# STM32WB06 register map
File version: 1.0
Registers are 32-bit, read-write, reset 0x0 unless marked. A register's access mark holds for its fields unless they carry their own. Offsets are from the block's base; [hi:lo] are bit positions; {n}, {i} and the like mark numbered series; 'fields as' and 'values as' point back to an identical list.

## RRM
Base 0x60001400
0x00 RRM_ID
  [3:0] IDENTIFICATION
0x04 RRM_CTRL
  [1:0] PRIORITY
0x10 UDRA_CTRL0
  [0] RELOAD_RDCFGPTR
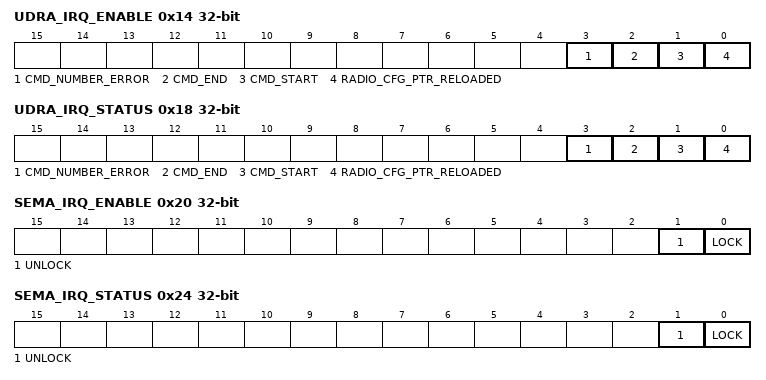
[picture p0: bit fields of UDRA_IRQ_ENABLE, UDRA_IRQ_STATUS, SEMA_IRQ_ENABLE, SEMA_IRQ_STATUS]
0x14 UDRA_IRQ_ENABLE
  [3] CMD_NUMBER_ERROR, [2] CMD_END, [1] CMD_START, [0] RADIO_CFG_PTR_RELOADED
0x18 UDRA_IRQ_STATUS
  fields as UDRA_IRQ_ENABLE
0x1C UDRA_RADIO_CFG_PTR
  [31:0] RADIO_CONFIG_ADDRESS
0x20 SEMA_IRQ_ENABLE
  [1] UNLOCK, [0] LOCK
0x24 SEMA_IRQ_STATUS
  [1] UNLOCK, [0] LOCK
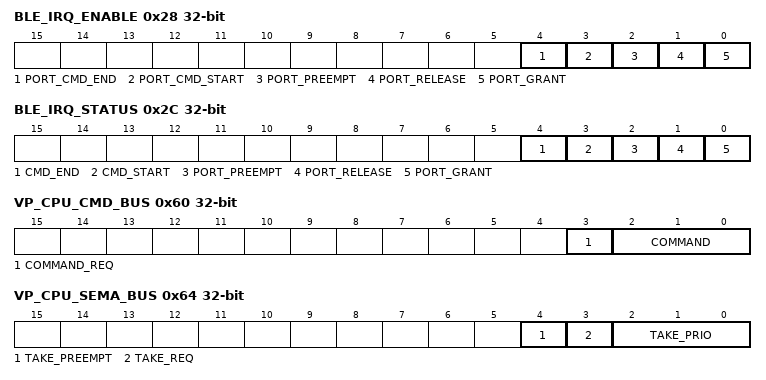
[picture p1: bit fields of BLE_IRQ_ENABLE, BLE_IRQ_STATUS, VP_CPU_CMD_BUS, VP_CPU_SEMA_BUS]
0x28 BLE_IRQ_ENABLE
  [4] PORT_CMD_END, [3] PORT_CMD_START, [2] PORT_PREEMPT, [1] PORT_RELEASE, [0] PORT_GRANT
0x2C BLE_IRQ_STATUS
  [4] CMD_END, [3] CMD_START, [2] PORT_PREEMPT, [1] PORT_RELEASE, [0] PORT_GRANT
0x60 VP_CPU_CMD_BUS
  [3] COMMAND_REQ, [2:0] COMMAND
0x64 VP_CPU_SEMA_BUS
  [4] TAKE_PREEMPT, [3] TAKE_REQ, [2:0] TAKE_PRIO
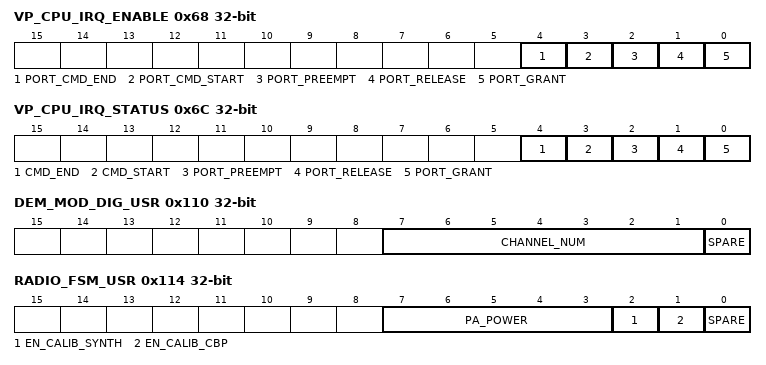
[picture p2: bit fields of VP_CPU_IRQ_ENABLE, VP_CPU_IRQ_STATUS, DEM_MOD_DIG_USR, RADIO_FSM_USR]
0x68 VP_CPU_IRQ_ENABLE
  fields as BLE_IRQ_ENABLE
0x6C VP_CPU_IRQ_STATUS
  fields as BLE_IRQ_STATUS
{0x100+4i} AA{i}_DIG_USR (i=0..3)
  [7:0] AA_{8i+7}_{8i}
0x110 DEM_MOD_DIG_USR
  [7:1] CHANNEL_NUM, [0] SPARE
0x114 RADIO_FSM_USR
  [7:3] PA_POWER, [2] EN_CALIB_SYNTH, [1] EN_CALIB_CBP, [0] SPARE
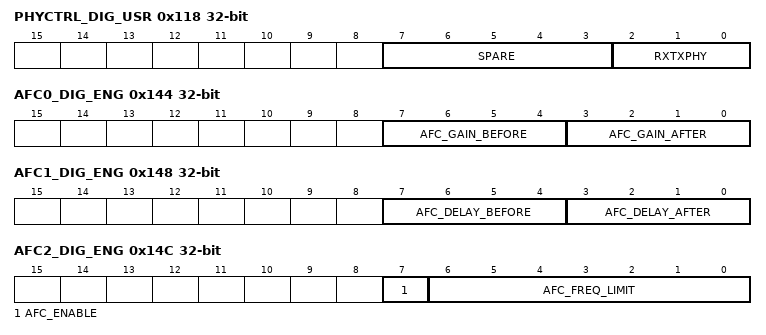
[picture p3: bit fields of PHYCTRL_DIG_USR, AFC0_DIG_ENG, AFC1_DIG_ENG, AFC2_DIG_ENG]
0x118 PHYCTRL_DIG_USR
  [7:3] SPARE, [2:0] RXTXPHY
0x144 AFC0_DIG_ENG
  [7:4] AFC_GAIN_BEFORE, [3:0] AFC_GAIN_AFTER
0x148 AFC1_DIG_ENG
  [7:4] AFC_DELAY_BEFORE, [3:0] AFC_DELAY_AFTER
0x14C AFC2_DIG_ENG
  [7] AFC_ENABLE, [6:0] AFC_FREQ_LIMIT
0x150 AFC3_DIG_ENG
  [7:0] AFC_MINMAX_LIMIT
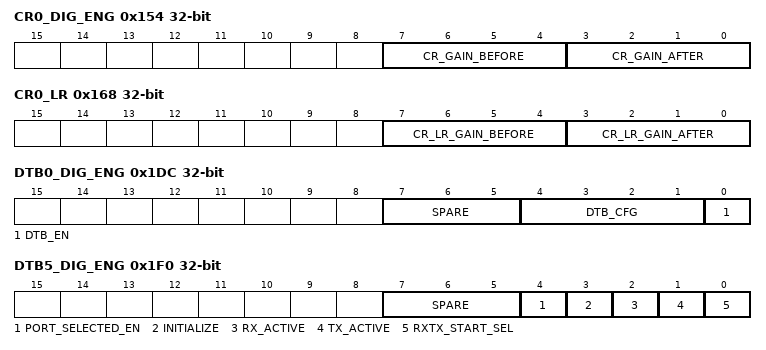
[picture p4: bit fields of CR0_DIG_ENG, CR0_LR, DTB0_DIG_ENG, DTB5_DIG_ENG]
0x154 CR0_DIG_ENG
  [7:4] CR_GAIN_BEFORE, [3:0] CR_GAIN_AFTER
0x168 CR0_LR
  [7:4] CR_LR_GAIN_BEFORE, [3:0] CR_LR_GAIN_AFTER
0x16C VIT_CONF_DIG_ENG
  [7:0] VIT_CONF
0x184 LR_PD_THR_DIG_ENG
  [7:0] LR_PD_THR
0x188 LR_RSSI_THR_DIG_ENG
  [7:0] LR_RSSI_THR
0x18C LR_AAC_THR_DIG_ENG
  [7:0] LR_AAC_THR
0x1DC DTB0_DIG_ENG
  [7:5] SPARE, [4:1] DTB_CFG, [0] DTB_EN
0x1F0 DTB5_DIG_ENG
  [7:5] SPARE, [4] PORT_SELECTED_EN, [3] INITIALIZE, [2] RX_ACTIVE, [1] TX_ACTIVE, [0] RXTX_START_SEL
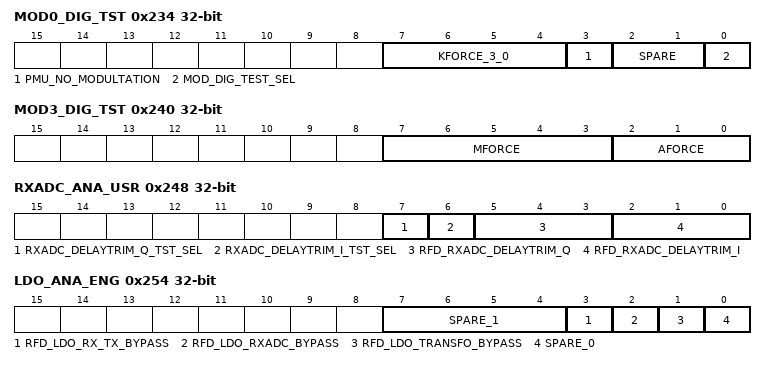
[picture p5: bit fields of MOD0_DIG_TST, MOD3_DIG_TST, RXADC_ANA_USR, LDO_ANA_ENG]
0x234 MOD0_DIG_TST
  [7:4] KFORCE_3_0, [3] PMU_NO_MODULTATION, [2:1] SPARE, [0] MOD_DIG_TEST_SEL
0x238 MOD1_DIG_TST
  [7:0] KFORCE_11_4
0x23C MOD2_DIG_TST
  [7:0] KFORCE_19_12
0x240 MOD3_DIG_TST
  [7:3] MFORCE, [2:0] AFORCE
0x248 RXADC_ANA_USR
  [7] RXADC_DELAYTRIM_Q_TST_SEL, [6] RXADC_DELAYTRIM_I_TST_SEL, [5:3] RFD_RXADC_DELAYTRIM_Q, [2:0] RFD_RXADC_DELAYTRIM_I
0x254 LDO_ANA_ENG
  [7:4] SPARE_1, [3] RFD_LDO_RX_TX_BYPASS, [2] RFD_LDO_RXADC_BYPASS, [1] RFD_LDO_TRANSFO_BYPASS, [0] SPARE_0
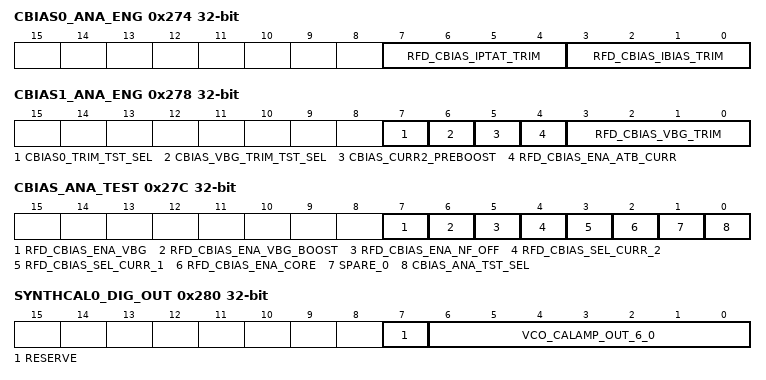
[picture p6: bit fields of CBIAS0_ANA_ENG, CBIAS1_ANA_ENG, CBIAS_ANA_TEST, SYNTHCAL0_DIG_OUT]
0x274 CBIAS0_ANA_ENG
  [7:4] RFD_CBIAS_IPTAT_TRIM, [3:0] RFD_CBIAS_IBIAS_TRIM
0x278 CBIAS1_ANA_ENG
  [7] CBIAS0_TRIM_TST_SEL, [6] CBIAS_VBG_TRIM_TST_SEL, [5] CBIAS_CURR2_PREBOOST, [4] RFD_CBIAS_ENA_ATB_CURR, [3:0] RFD_CBIAS_VBG_TRIM
0x27C CBIAS_ANA_TEST
  [7] RFD_CBIAS_ENA_VBG, [6] RFD_CBIAS_ENA_VBG_BOOST, [5] RFD_CBIAS_ENA_NF_OFF, [4] RFD_CBIAS_SEL_CURR_2, [3] RFD_CBIAS_SEL_CURR_1, [2] RFD_CBIAS_ENA_CORE, [1] SPARE_0, [0] CBIAS_ANA_TST_SEL
0x280 SYNTHCAL0_DIG_OUT
  [7] RESERVE, [6:0] VCO_CALAMP_OUT_6_0
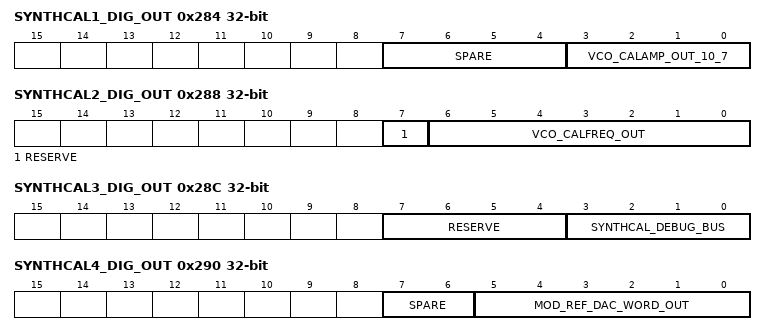
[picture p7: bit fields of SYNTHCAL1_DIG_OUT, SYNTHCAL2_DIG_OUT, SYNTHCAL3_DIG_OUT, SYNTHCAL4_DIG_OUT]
0x284 SYNTHCAL1_DIG_OUT
  [7:4] SPARE, [3:0] VCO_CALAMP_OUT_10_7
0x288 SYNTHCAL2_DIG_OUT
  [7] RESERVE, [6:0] VCO_CALFREQ_OUT
0x28C SYNTHCAL3_DIG_OUT
  [7:4] RESERVE, [3:0] SYNTHCAL_DEBUG_BUS
0x290 SYNTHCAL4_DIG_OUT
  [7:6] SPARE, [5:0] MOD_REF_DAC_WORD_OUT
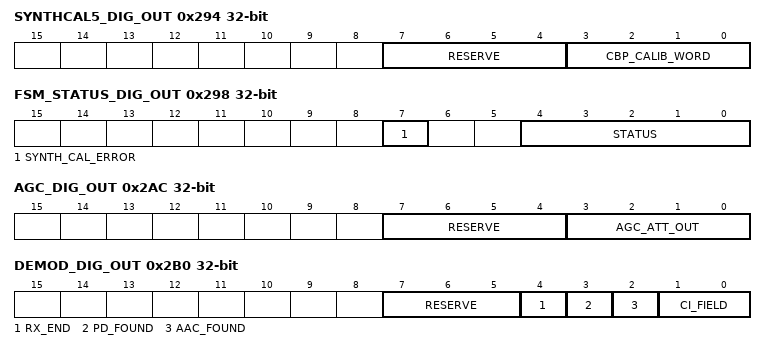
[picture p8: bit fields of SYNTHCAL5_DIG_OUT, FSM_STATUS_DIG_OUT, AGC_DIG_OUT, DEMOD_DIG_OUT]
0x294 SYNTHCAL5_DIG_OUT
  [7:4] RESERVE, [3:0] CBP_CALIB_WORD
0x298 FSM_STATUS_DIG_OUT
  [7] SYNTH_CAL_ERROR, [4:0] STATUS
0x29C IRQ_STATUS_DIG_OUT
  [7:0] RESERVE
0x2A4 RSSI0_DIG_OUT
  [7:0] RSSI_MEAS_OUT_7_0
0x2A8 RSSI1_DIG_OUT
  [7:0] RSSI_MEAS_OUT_15_8
0x2AC AGC_DIG_OUT
  [7:4] RESERVE, [3:0] AGC_ATT_OUT
0x2B0 DEMOD_DIG_OUT
  [7:5] RESERVE, [4] RX_END, [3] PD_FOUND, [2] AAC_FOUND, [1:0] CI_FIELD
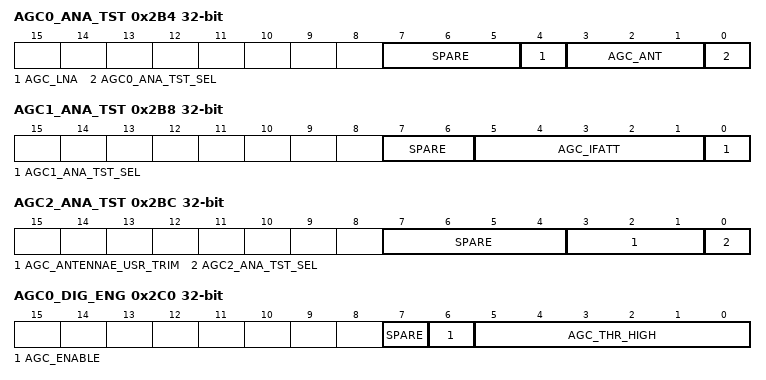
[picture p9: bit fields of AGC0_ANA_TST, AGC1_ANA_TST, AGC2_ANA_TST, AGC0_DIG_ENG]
0x2B4 AGC0_ANA_TST
  [7:5] SPARE, [4] AGC_LNA, [3:1] AGC_ANT, [0] AGC0_ANA_TST_SEL
0x2B8 AGC1_ANA_TST
  [7:6] SPARE, [5:1] AGC_IFATT, [0] AGC1_ANA_TST_SEL
0x2BC AGC2_ANA_TST
  [7:4] SPARE, [3:1] AGC_ANTENNAE_USR_TRIM, [0] AGC2_ANA_TST_SEL
0x2C0 AGC0_DIG_ENG
  [7] SPARE, [6] AGC_ENABLE, [5:0] AGC_THR_HIGH
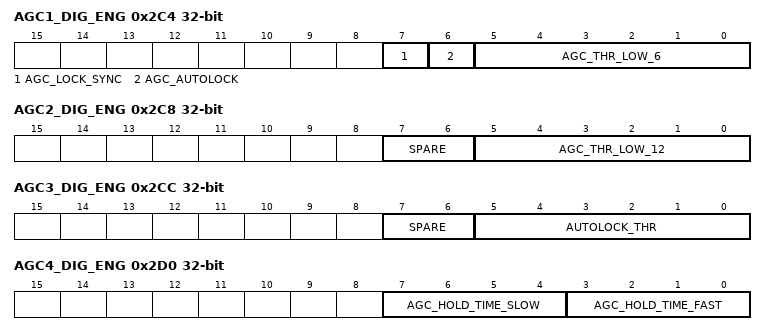
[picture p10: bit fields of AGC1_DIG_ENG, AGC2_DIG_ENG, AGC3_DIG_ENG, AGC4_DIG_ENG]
0x2C4 AGC1_DIG_ENG
  [7] AGC_LOCK_SYNC, [6] AGC_AUTOLOCK, [5:0] AGC_THR_LOW_6
0x2C8 AGC2_DIG_ENG
  [7:6] SPARE, [5:0] AGC_THR_LOW_12
0x2CC AGC3_DIG_ENG
  [7:6] SPARE, [5:0] AUTOLOCK_THR
0x2D0 AGC4_DIG_ENG
  [7:4] AGC_HOLD_TIME_SLOW, [3:0] AGC_HOLD_TIME_FAST
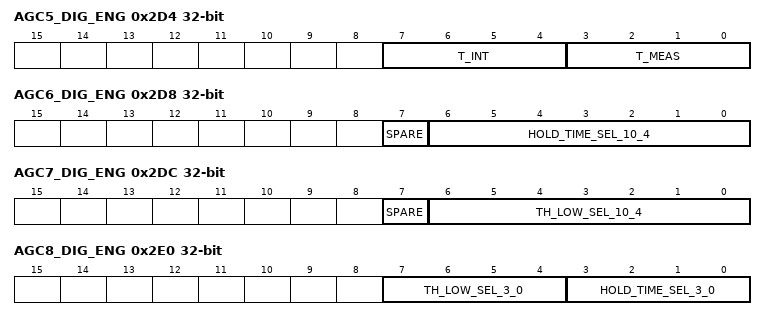
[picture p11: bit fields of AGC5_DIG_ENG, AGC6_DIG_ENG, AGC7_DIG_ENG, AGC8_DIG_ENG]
0x2D4 AGC5_DIG_ENG
  [7:4] T_INT, [3:0] T_MEAS
0x2D8 AGC6_DIG_ENG
  [7] SPARE, [6:0] HOLD_TIME_SEL_10_4
0x2DC AGC7_DIG_ENG
  [7] SPARE, [6:0] TH_LOW_SEL_10_4
0x2E0 AGC8_DIG_ENG
  [7:4] TH_LOW_SEL_3_0, [3:0] HOLD_TIME_SEL_3_0
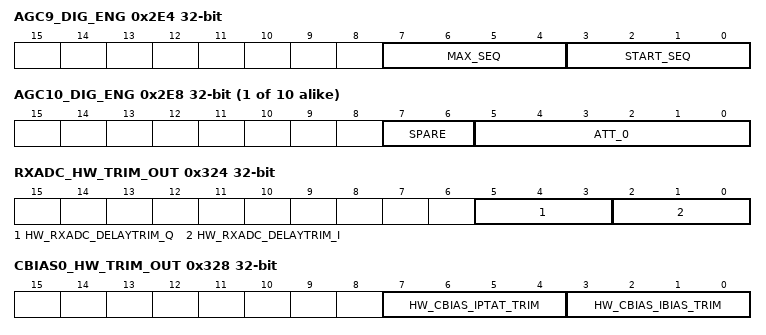
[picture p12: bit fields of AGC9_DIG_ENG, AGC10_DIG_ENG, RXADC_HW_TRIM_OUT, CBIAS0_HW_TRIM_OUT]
0x2E4 AGC9_DIG_ENG
  [7:4] MAX_SEQ, [3:0] START_SEQ
{0x2C0+4i} AGC{i}_DIG_ENG (i=10..19)
  [7:6] SPARE, [5:0] ATT_{i-10}
0x310 AGC20_DIG_ENG
  [7:0] I_GAIN_COMP
0x324 RXADC_HW_TRIM_OUT
  [5:3] HW_RXADC_DELAYTRIM_Q, [2:0] HW_RXADC_DELAYTRIM_I
0x328 CBIAS0_HW_TRIM_OUT
  [7:4] HW_CBIAS_IPTAT_TRIM, [3:0] HW_CBIAS_IBIAS_TRIM
0x32C CBIAS1_HW_TRIM_OUT
  [3:0] HW_CBIAS_VBG_TRIM
0x330 AGC_HW_TRIM_OUT
  [3:1] HW_AGC_ANTENNAE_TRIM
